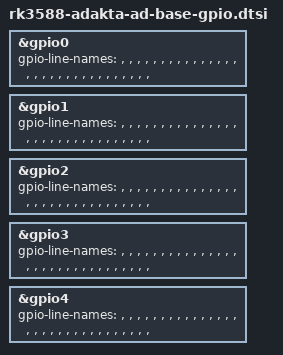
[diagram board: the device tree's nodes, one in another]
// SPDX-License-Identifier: (GPL-2.0+ OR MIT)
/*
 * Copyright (c) 2024 Adakta, Ltd.
 *
 */

&gpio0 {
	gpio-line-names =
		/* GPIO0_A0-A3 */
		"", "", "", "",
		/* GPIO0_A4-A7 */
		"", "", "", "",

		/* GPIO0_B0-B3 */
		"", "", "", "",
		/* GPIO0_B4-B7 */
		"", "", "", "",

		/* GPIO0_C0-C3 */
		"", "", "", "",
		/* GPIO0_C4-C7 */
		"", "", "", "",

		/* GPIO0_D0-D3 */
		"", "", "", "",
		/* GPIO0_D4-D7 */
		"", "", "", "";
};

&gpio1 {
	gpio-line-names =
		/* GPIO1_A0-A3 */
		"", "", "", "",
		/* GPIO1_A4-A7 */
		"", "", "", "",

		/* GPIO1_B0-B3 */
		"", "", "", "",
		/* GPIO1_B4-B7 */
		"", "", "", "",

		/* GPIO1_C0-C3 */
		"", "", "", "",
		/* GPIO1_C4-C7 */
		"", "", "", "",

		/* GPIO1_D0-D3 */
		"", "", "", "",
		/* GPIO1_D4-D7 */
		"", "", "", "";
};

&gpio2 {
	gpio-line-names =
		/* GPIO2_A0-A3 */
		"", "", "", "",
		/* GPIO2_A4-A7 */
		"", "", "", "",

		/* GPIO2_B0-B3 */
		"", "", "", "",
		/* GPIO2_B4-B7 */
		"", "", "", "",

		/* GPIO2_C0-C3 */
		"", "", "", "",
		/* GPIO2_C4-C7 */
		"", "", "", "",

		/* GPIO2_D0-D3 */
		"", "", "", "",
		/* GPIO2_D4-D7 */
		"", "", "", "";
};

&gpio3 {
	gpio-line-names =
		/* GPIO3_A0-A3 */
		"", "", "", "",
		/* GPIO3_A4-A7 */
		"", "", "", "",

		/* GPIO3_B0-B3 */
		"", "", "", "",
		/* GPIO3_B4-B7 */
		"", "", "", "",

		/* GPIO3_C0-C3 */
		"", "", "", "",
		/* GPIO3_C4-C7 */
		"", "", "", "",

		/* GPIO3_D0-D3 */
		"", "", "", "",
		/* GPIO3_D4-D7 */
		"", "", "", "";
};

&gpio4 {
	gpio-line-names =
		/* GPIO4_A0-A3 */
		"", "", "", "",
		/* GPIO4_A4-A7 */
		"", "", "", "",

		/* GPIO4_B0-B3 */
		"", "", "", "",
		/* GPIO4_B4-B7 */
		"", "", "", "",

		/* GPIO4_C0-C3 */
		"", "", "", "",
		/* GPIO4_C4-C7 */
		"", "", "", "",

		/* GPIO4_D0-D3 */
		"", "", "", "",
		/* GPIO4_D4-D7 */
		"", "", "", "";
};
